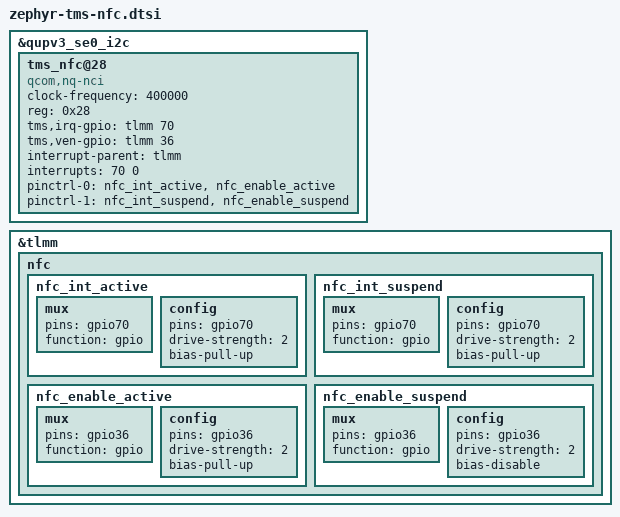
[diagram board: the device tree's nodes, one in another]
&qupv3_se0_i2c {
    status = "ok";
    tms_nfc@28 {
        clock-frequency = <400000>;
        status = "ok";
        compatible = "qcom,nq-nci";
        reg = <0x28>;
        tms,irq-gpio      = <&tlmm 70 0x00>;
        tms,ven-gpio      = <&tlmm 36 0x00>;
        interrupt-parent = <&tlmm>;
        interrupts = <70 0>;
        interrupt-names = "nfc_irq";
        pinctrl-names = "nfc_active", "nfc_suspend";
        pinctrl-0 = <&nfc_int_active &nfc_enable_active>;
        pinctrl-1 = <&nfc_int_suspend &nfc_enable_suspend>;
        };
};

&tlmm {
	nfc {
		nfc_int_active: nfc_int_active {
			/* active state */
			mux {
				/* GPIO 70 NFC Read Interrupt */
				pins = "gpio70";
				function = "gpio";
			};

			config {
				pins = "gpio70";
				drive-strength = <2>; /* 2 MA */
				bias-pull-up;
			};
		};

		nfc_int_suspend: nfc_int_suspend {
			/* sleep state */
			mux {
				/* GPIO 70 NFC Read Interrupt */
				pins = "gpio70";
				function = "gpio";
			};

			config {
				pins = "gpio70";
				drive-strength = <2>; /* 2 MA */
				bias-pull-up;
			};
		};

		nfc_enable_active: nfc_enable_active {
			/* active state */
			mux {
				/* 36: Enable */
				pins = "gpio36";
				function = "gpio";
			};

			config {
				pins = "gpio36";
				drive-strength = <2>; /* 2 MA */
				bias-pull-up;
			};
		};

		nfc_enable_suspend: nfc_enable_suspend {
			/* sleep state */
			mux {
				/* 36: Enable */
				pins = "gpio36";
				function = "gpio";
			};

			config {
				pins = "gpio36";
				drive-strength = <2>; /* 2 MA */
				bias-disable;
			};
		};
	};
}; //tlmm
